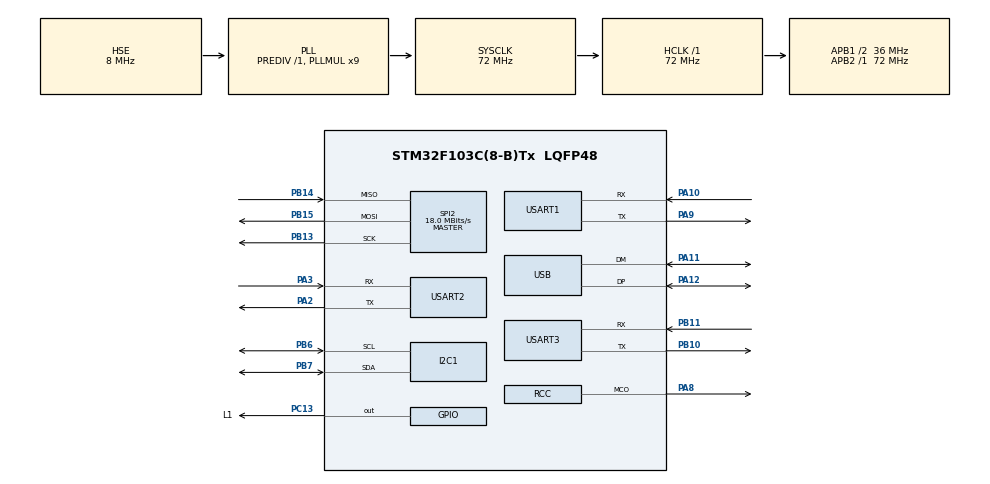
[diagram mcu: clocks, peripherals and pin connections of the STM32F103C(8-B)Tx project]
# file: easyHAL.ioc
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FREERTOS.Tasks01=testTask,0,128,test_Task,Default,NULL,Dynamic,NULL,NULL
FREERTOS.configUSE_NEWLIB_REENTRANT=1
Mcu.Family=STM32F1
Mcu.Name=STM32F103C(8-B)Tx
Mcu.Package=LQFP48
NVIC.PriorityGroup=NVIC_PRIORITYGROUP_4
NVIC.USART1_IRQn=true\:5\:0\:false\:false\:true\:true\:true\:true\:true
NVIC.USB_LP_CAN1_RX0_IRQn=true\:5\:0\:false\:false\:true\:true\:false\:true\:true
PA10.Mode=Asynchronous
PA10.Signal=USART1_RX
PA11.Mode=Device
PA11.Signal=USB_DM
PA12.Mode=Device
PA12.Signal=USB_DP
PA13.Mode=Serial_Wire
PA13.Signal=SYS_JTMS-SWDIO
PA14.Mode=Serial_Wire
PA14.Signal=SYS_JTCK-SWCLK
PA2.Mode=Asynchronous
PA2.Signal=USART2_TX
PA3.Mode=Asynchronous
PA3.Signal=USART2_RX
PA8.Mode=Clock-out
PA8.Signal=RCC_MCO
PA9.Mode=Asynchronous
PA9.Signal=USART1_TX
PB10.Mode=Asynchronous
PB10.Signal=USART3_TX
PB11.Mode=Asynchronous
PB11.Signal=USART3_RX
PB13.Mode=Full_Duplex_Master
PB13.Signal=SPI2_SCK
PB14.Mode=Full_Duplex_Master
PB14.Signal=SPI2_MISO
PB15.Mode=Full_Duplex_Master
PB15.Signal=SPI2_MOSI
PB6.Mode=I2C
PB6.Signal=I2C1_SCL
PB7.Mode=I2C
PB7.Signal=I2C1_SDA
PC13-TAMPER-RTC.GPIO_Label=L1
PC13-TAMPER-RTC.Signal=GPIO_Output
PC14-OSC32_IN.Mode=LSE-External-Clock-Source
PC14-OSC32_IN.Signal=RCC_OSC32_IN
PC15-OSC32_OUT.Mode=LSE-External-Clock-Source
PC15-OSC32_OUT.Signal=RCC_OSC32_OUT
PD0-OSC_IN.Mode=HSE-External-Clock-Source
PD0-OSC_IN.Signal=RCC_OSC_IN
PD1-OSC_OUT.Mode=HSE-External-Clock-Source
PD1-OSC_OUT.Signal=RCC_OSC_OUT
ProjectManager.HeapSize=0x200
ProjectManager.StackSize=0x400
ProjectManager.TargetToolchain=STM32CubeIDE
RCC.AHBFreq_Value=72000000
RCC.APB1CLKDivider=RCC_HCLK_DIV2
RCC.APB1Freq_Value=36000000
RCC.APB1TimFreq_Value=72000000
RCC.APB2Freq_Value=72000000
RCC.APB2TimFreq_Value=72000000
RCC.HCLKFreq_Value=72000000
RCC.PLLMUL=RCC_PLL_MUL9
RCC.RCC_MCOSource=RCC_MCO1SOURCE_PLLCLK
RCC.SYSCLKFreq_VALUE=72000000
RCC.SYSCLKSource=RCC_SYSCLKSOURCE_PLLCLK
RCC.USBFreq_Value=48000000
RCC.USBPrescaler=RCC_USBCLKSOURCE_PLL_DIV1_5
SPI2.CalculateBaudRate=18.0 MBits/s
SPI2.Direction=SPI_DIRECTION_2LINES
SPI2.Mode=SPI_MODE_MASTER
SPI2.VirtualType=VM_MASTER
USART1.Parity=PARITY_EVEN
USART1.VirtualMode=VM_ASYNC
USART2.VirtualMode=VM_ASYNC
USART3.VirtualMode=VM_ASYNC
USB_DEVICE.CLASS_NAME_FS=CDC
USB_DEVICE.VirtualMode=Cdc
USB_DEVICE.VirtualModeFS=Cdc_FS
VP_FREERTOS_VS_CMSIS_V1.Mode=CMSIS_V1
VP_USB_DEVICE_VS_USB_DEVICE_CDC_FS.Mode=CDC_FS
board=custom

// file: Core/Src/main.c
/* USER CODE BEGIN Header */
/**
  ******************************************************************************
  * @file           : main.c
  * @brief          : Main program body
  ******************************************************************************
  * @attention
  *
  * Copyright (c) 2025 STMicroelectronics.
  * All rights reserved.
  *
  * This software is licensed under terms that can be found in the LICENSE file
  * in the root directory of this software component.
  * If no LICENSE file comes with this software, it is provided AS-IS.
  *
  ******************************************************************************
  */
/* USER CODE END Header */
#include "main.h"
#include "cmsis_os.h"
#include "usb_device.h"

/* USER CODE BEGIN Includes */

#include <stdio.h>
#include "../extra/easyHAL/easyi2c.h"

/* USER CODE END Includes */

I2C_HandleTypeDef hi2c1;

SPI_HandleTypeDef hspi2;

UART_HandleTypeDef huart1;
UART_HandleTypeDef huart2;
UART_HandleTypeDef huart3;

osThreadId testTaskHandle;

void SystemClock_Config(void);
static void MX_GPIO_Init(void);
static void MX_USART1_UART_Init(void);
static void MX_I2C1_Init(void);
static void MX_SPI2_Init(void);
static void MX_USART2_UART_Init(void);
static void MX_USART3_UART_Init(void);
void test_Task(void const * argument);

/* USER CODE BEGIN PFP */
#ifdef __GNUC__

#define PUTCHAR_PROTOTYPE int __io_putchar(int ch)

#else

#define PUTCHAR_PROTOTYPE int fputc(int ch, FILE *f)

#endif

PUTCHAR_PROTOTYPE
{
	HAL_UART_Transmit(&huart2, (uint8_t *)&ch, 1, 0xFFFF);
}
/* USER CODE END PFP */

int main(void)
{

  /* MCU Configuration--------------------------------------------------------*/

  /* Reset of all peripherals, Initializes the Flash interface and the Systick. */
  HAL_Init();

  /* Configure the system clock */
  SystemClock_Config();

  /* Initialize all configured peripherals */
  MX_GPIO_Init();
  MX_USART1_UART_Init();
  MX_I2C1_Init();
  MX_SPI2_Init();
  MX_USART2_UART_Init();
  MX_USART3_UART_Init();

  /* Create the thread(s) */
  /* definition and creation of testTask */
  osThreadDef(testTask, test_Task, osPriorityNormal, 0, 128);
  testTaskHandle = osThreadCreate(osThread(testTask), NULL);

  /* Start scheduler */
  osKernelStart();

  /* We should never get here as control is now taken by the scheduler */

  /* Infinite loop */
  while (1)
  {

  }
}

void SystemClock_Config(void)
{
  RCC_OscInitTypeDef RCC_OscInitStruct = {0};
  RCC_ClkInitTypeDef RCC_ClkInitStruct = {0};
  RCC_PeriphCLKInitTypeDef PeriphClkInit = {0};

  /** Initializes the RCC Oscillators according to the specified parameters
  * in the RCC_OscInitTypeDef structure.
  */
  RCC_OscInitStruct.OscillatorType = RCC_OSCILLATORTYPE_HSE;
  RCC_OscInitStruct.HSEState = RCC_HSE_BYPASS;
  RCC_OscInitStruct.HSEPredivValue = RCC_HSE_PREDIV_DIV1;
  RCC_OscInitStruct.HSIState = RCC_HSI_ON;
  RCC_OscInitStruct.PLL.PLLState = RCC_PLL_ON;
  RCC_OscInitStruct.PLL.PLLSource = RCC_PLLSOURCE_HSE;
  RCC_OscInitStruct.PLL.PLLMUL = RCC_PLL_MUL9;
  if (HAL_RCC_OscConfig(&RCC_OscInitStruct) != HAL_OK)
  {
    Error_Handler();
  }

  /** Initializes the CPU, AHB and APB buses clocks
  */
  RCC_ClkInitStruct.ClockType = RCC_CLOCKTYPE_HCLK|RCC_CLOCKTYPE_SYSCLK
                              |RCC_CLOCKTYPE_PCLK1|RCC_CLOCKTYPE_PCLK2;
  RCC_ClkInitStruct.SYSCLKSource = RCC_SYSCLKSOURCE_PLLCLK;
  RCC_ClkInitStruct.AHBCLKDivider = RCC_SYSCLK_DIV1;
  RCC_ClkInitStruct.APB1CLKDivider = RCC_HCLK_DIV2;
  RCC_ClkInitStruct.APB2CLKDivider = RCC_HCLK_DIV1;

  if (HAL_RCC_ClockConfig(&RCC_ClkInitStruct, FLASH_LATENCY_2) != HAL_OK)
  {
    Error_Handler();
  }
  PeriphClkInit.PeriphClockSelection = RCC_PERIPHCLK_USB;
  PeriphClkInit.UsbClockSelection = RCC_USBCLKSOURCE_PLL_DIV1_5;
  if (HAL_RCCEx_PeriphCLKConfig(&PeriphClkInit) != HAL_OK)
  {
    Error_Handler();
  }
  HAL_RCC_MCOConfig(RCC_MCO, RCC_MCO1SOURCE_PLLCLK, RCC_MCODIV_1);
}

static void MX_I2C1_Init(void)
{

  hi2c1.Instance = I2C1;
  hi2c1.Init.ClockSpeed = 100000;
  hi2c1.Init.DutyCycle = I2C_DUTYCYCLE_2;
  hi2c1.Init.OwnAddress1 = 0;
  hi2c1.Init.AddressingMode = I2C_ADDRESSINGMODE_7BIT;
  hi2c1.Init.DualAddressMode = I2C_DUALADDRESS_DISABLE;
  hi2c1.Init.OwnAddress2 = 0;
  hi2c1.Init.GeneralCallMode = I2C_GENERALCALL_DISABLE;
  hi2c1.Init.NoStretchMode = I2C_NOSTRETCH_DISABLE;
  if (HAL_I2C_Init(&hi2c1) != HAL_OK)
  {
    Error_Handler();
  }

}

static void MX_SPI2_Init(void)
{

  /* SPI2 parameter configuration*/
  hspi2.Instance = SPI2;
  hspi2.Init.Mode = SPI_MODE_MASTER;
  hspi2.Init.Direction = SPI_DIRECTION_2LINES;
  hspi2.Init.DataSize = SPI_DATASIZE_8BIT;
  hspi2.Init.CLKPolarity = SPI_POLARITY_LOW;
  hspi2.Init.CLKPhase = SPI_PHASE_1EDGE;
  hspi2.Init.NSS = SPI_NSS_SOFT;
  hspi2.Init.BaudRatePrescaler = SPI_BAUDRATEPRESCALER_2;
  hspi2.Init.FirstBit = SPI_FIRSTBIT_MSB;
  hspi2.Init.TIMode = SPI_TIMODE_DISABLE;
  hspi2.Init.CRCCalculation = SPI_CRCCALCULATION_DISABLE;
  hspi2.Init.CRCPolynomial = 10;
  if (HAL_SPI_Init(&hspi2) != HAL_OK)
  {
    Error_Handler();
  }

}

static void MX_USART1_UART_Init(void)
{

  huart1.Instance = USART1;
  huart1.Init.BaudRate = 115200;
  huart1.Init.WordLength = UART_WORDLENGTH_8B;
  huart1.Init.StopBits = UART_STOPBITS_1;
  huart1.Init.Parity = UART_PARITY_EVEN;
  huart1.Init.Mode = UART_MODE_TX_RX;
  huart1.Init.HwFlowCtl = UART_HWCONTROL_NONE;
  huart1.Init.OverSampling = UART_OVERSAMPLING_16;
  if (HAL_UART_Init(&huart1) != HAL_OK)
  {
    Error_Handler();
  }

}

static void MX_USART2_UART_Init(void)
{

  huart2.Instance = USART2;
  huart2.Init.BaudRate = 115200;
  huart2.Init.WordLength = UART_WORDLENGTH_8B;
  huart2.Init.StopBits = UART_STOPBITS_1;
  huart2.Init.Parity = UART_PARITY_NONE;
  huart2.Init.Mode = UART_MODE_TX_RX;
  huart2.Init.HwFlowCtl = UART_HWCONTROL_NONE;
  huart2.Init.OverSampling = UART_OVERSAMPLING_16;
  if (HAL_UART_Init(&huart2) != HAL_OK)
  {
    Error_Handler();
  }

}

static void MX_USART3_UART_Init(void)
{

  huart3.Instance = USART3;
  huart3.Init.BaudRate = 115200;
  huart3.Init.WordLength = UART_WORDLENGTH_8B;
  huart3.Init.StopBits = UART_STOPBITS_1;
  huart3.Init.Parity = UART_PARITY_NONE;
  huart3.Init.Mode = UART_MODE_TX_RX;
  huart3.Init.HwFlowCtl = UART_HWCONTROL_NONE;
  huart3.Init.OverSampling = UART_OVERSAMPLING_16;
  if (HAL_UART_Init(&huart3) != HAL_OK)
  {
    Error_Handler();
  }

}

static void MX_GPIO_Init(void)
{
  GPIO_InitTypeDef GPIO_InitStruct = {0};

  /* GPIO Ports Clock Enable */
  __HAL_RCC_GPIOC_CLK_ENABLE();
  __HAL_RCC_GPIOD_CLK_ENABLE();
  __HAL_RCC_GPIOA_CLK_ENABLE();
  __HAL_RCC_GPIOB_CLK_ENABLE();

  /*Configure GPIO pin Output Level */
  HAL_GPIO_WritePin(L1_GPIO_Port, L1_Pin, GPIO_PIN_RESET);

  /*Configure GPIO pin : L1_Pin */
  GPIO_InitStruct.Pin = L1_Pin;
  GPIO_InitStruct.Mode = GPIO_MODE_OUTPUT_PP;
  GPIO_InitStruct.Pull = GPIO_NOPULL;
  GPIO_InitStruct.Speed = GPIO_SPEED_FREQ_LOW;
  HAL_GPIO_Init(L1_GPIO_Port, &GPIO_InitStruct);

  /*Configure GPIO pin : PA8 */
  GPIO_InitStruct.Pin = GPIO_PIN_8;
  GPIO_InitStruct.Mode = GPIO_MODE_AF_PP;
  GPIO_InitStruct.Speed = GPIO_SPEED_FREQ_LOW;
  HAL_GPIO_Init(GPIOA, &GPIO_InitStruct);

}

void test_Task(void const * argument)
{
  /* init code for USB_DEVICE */
  MX_USB_DEVICE_Init();
  for(;;)
  {
    osDelay(1);
  }
}

void Error_Handler(void)
{
  __disable_irq();
  while (1)
  {
  }
}
